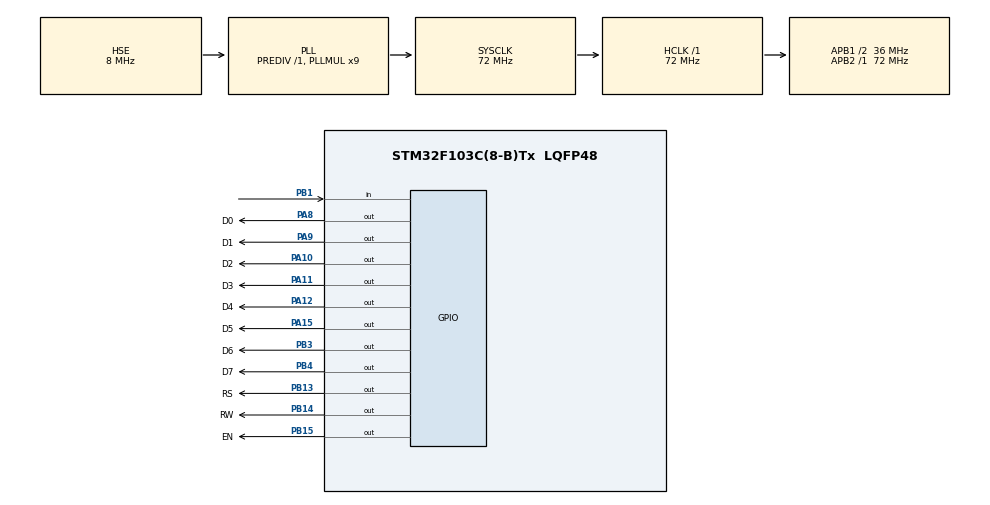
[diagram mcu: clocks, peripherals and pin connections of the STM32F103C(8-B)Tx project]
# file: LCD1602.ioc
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Mcu.Family=STM32F1
Mcu.Name=STM32F103C(8-B)Tx
Mcu.Package=LQFP48
NVIC.PriorityGroup=NVIC_PRIORITYGROUP_4
NVIC.TIM1_UP_IRQn=true\:0\:0\:false\:false\:true\:true\:true\:true
PA10.GPIO_Label=D2
PA10.GPIO_Speed=GPIO_SPEED_FREQ_HIGH
PA10.Signal=GPIO_Output
PA11.GPIO_Label=D3
PA11.GPIO_Speed=GPIO_SPEED_FREQ_HIGH
PA11.Signal=GPIO_Output
PA12.GPIO_Label=D4
PA12.GPIO_Speed=GPIO_SPEED_FREQ_HIGH
PA12.Signal=GPIO_Output
PA13.Mode=Serial_Wire
PA13.Signal=SYS_JTMS-SWDIO
PA14.Mode=Serial_Wire
PA14.Signal=SYS_JTCK-SWCLK
PA15.GPIO_Label=D5
PA15.GPIO_Speed=GPIO_SPEED_FREQ_HIGH
PA15.Signal=GPIO_Output
PA8.GPIO_Label=D0
PA8.GPIO_Speed=GPIO_SPEED_FREQ_HIGH
PA8.Signal=GPIO_Output
PA9.GPIO_Label=D1
PA9.GPIO_Speed=GPIO_SPEED_FREQ_HIGH
PA9.Signal=GPIO_Output
PB1.GPIO_PuPd=GPIO_PULLUP
PB1.Signal=GPIO_Input
PB13.GPIO_Label=RS
PB13.GPIO_Speed=GPIO_SPEED_FREQ_HIGH
PB13.Signal=GPIO_Output
PB14.GPIO_Label=RW
PB14.GPIO_Speed=GPIO_SPEED_FREQ_HIGH
PB14.Signal=GPIO_Output
PB15.GPIO_Label=EN
PB15.GPIO_Speed=GPIO_SPEED_FREQ_HIGH
PB15.Signal=GPIO_Output
PB3.GPIO_Label=D6
PB3.GPIO_Speed=GPIO_SPEED_FREQ_HIGH
PB3.Signal=GPIO_Output
PB4.GPIO_Label=D7
PB4.GPIO_Speed=GPIO_SPEED_FREQ_HIGH
PB4.Signal=GPIO_Output
PD0-OSC_IN.Mode=HSE-External-Oscillator
PD0-OSC_IN.Signal=RCC_OSC_IN
PD1-OSC_OUT.Mode=HSE-External-Oscillator
PD1-OSC_OUT.Signal=RCC_OSC_OUT
ProjectManager.HeapSize=0x00
ProjectManager.StackSize=0x400
ProjectManager.TargetToolchain=MDK-ARM V5.32
RCC.AHBFreq_Value=72000000
RCC.APB1CLKDivider=RCC_HCLK_DIV2
RCC.APB1Freq_Value=36000000
RCC.APB1TimFreq_Value=72000000
RCC.APB2Freq_Value=72000000
RCC.APB2TimFreq_Value=72000000
RCC.HCLKFreq_Value=72000000
RCC.PLLMUL=RCC_PLL_MUL9
RCC.PLLSourceVirtual=RCC_PLLSOURCE_HSE
RCC.SYSCLKFreq_VALUE=72000000
RCC.SYSCLKSource=RCC_SYSCLKSOURCE_PLLCLK
RCC.USBFreq_Value=72000000
TIM1.Period=200-1
TIM1.Prescaler=7200-1
VP_TIM1_VS_ClockSourceINT.Mode=Internal
board=custom

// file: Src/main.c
/* USER CODE BEGIN Header */
/**
 ******************************************************************************
 * @file           : main.c
 * @brief          : Main program body
 ******************************************************************************
 * @attention
 *
 * Copyright (c) 2024 STMicroelectronics.
 * All rights reserved.
 *
 * This software is licensed under terms that can be found in the LICENSE file
 * in the root directory of this software component.
 * If no LICENSE file comes with this software, it is provided AS-IS.
 *
 ******************************************************************************
 */
/* USER CODE END Header */
#include "main.h"
#include "tim.h"
#include "gpio.h"

/* USER CODE BEGIN Includes */
#include "show.h"
/* USER CODE END Includes */

void SystemClock_Config(void);

/* USER CODE BEGIN 0 */
extern uint8_t state;
/* USER CODE END 0 */

int main(void)
{

  /* MCU Configuration--------------------------------------------------------*/

  /* Reset of all peripherals, Initializes the Flash interface and the Systick. */
  HAL_Init();

  /* Configure the system clock */
  SystemClock_Config();

  /* Initialize all configured peripherals */
  MX_GPIO_Init();
  MX_TIM1_Init();
  /* USER CODE BEGIN 2 */
  HAL_TIM_Base_Start_IT(&htim1);

  WriteCommand(0x01); // 清除显示
  WriteCommand(0x06); // AC自增，显示不发生位移
  // WriteCommand(0x0f); // 开显示，游标显示，闪烁
  WriteCommand(0x0c); // 开显示，不游标显示，不闪烁
  WriteCommand(0x3c); // 8位数据总线两行显示

  // 显示
  WriteCommand(0x80); // 设置DDRAM地址
  WriteData('a');
  /* USER CODE END 2 */

  /* Infinite loop */
  /* USER CODE BEGIN WHILE */
  while (1)
  {
    WriteCommand(0x80); // 设置DDRAM地址
    WriteData(state + '0');
    /* USER CODE END WHILE */

  }
}

void SystemClock_Config(void)
{
  RCC_OscInitTypeDef RCC_OscInitStruct = {0};
  RCC_ClkInitTypeDef RCC_ClkInitStruct = {0};

  /** Initializes the RCC Oscillators according to the specified parameters
   * in the RCC_OscInitTypeDef structure.
   */
  RCC_OscInitStruct.OscillatorType = RCC_OSCILLATORTYPE_HSE;
  RCC_OscInitStruct.HSEState = RCC_HSE_ON;
  RCC_OscInitStruct.HSEPredivValue = RCC_HSE_PREDIV_DIV1;
  RCC_OscInitStruct.HSIState = RCC_HSI_ON;
  RCC_OscInitStruct.PLL.PLLState = RCC_PLL_ON;
  RCC_OscInitStruct.PLL.PLLSource = RCC_PLLSOURCE_HSE;
  RCC_OscInitStruct.PLL.PLLMUL = RCC_PLL_MUL9;
  if (HAL_RCC_OscConfig(&RCC_OscInitStruct) != HAL_OK)
  {
    Error_Handler();
  }

  /** Initializes the CPU, AHB and APB buses clocks
   */
  RCC_ClkInitStruct.ClockType = RCC_CLOCKTYPE_HCLK | RCC_CLOCKTYPE_SYSCLK | RCC_CLOCKTYPE_PCLK1 | RCC_CLOCKTYPE_PCLK2;
  RCC_ClkInitStruct.SYSCLKSource = RCC_SYSCLKSOURCE_PLLCLK;
  RCC_ClkInitStruct.AHBCLKDivider = RCC_SYSCLK_DIV1;
  RCC_ClkInitStruct.APB1CLKDivider = RCC_HCLK_DIV2;
  RCC_ClkInitStruct.APB2CLKDivider = RCC_HCLK_DIV1;

  if (HAL_RCC_ClockConfig(&RCC_ClkInitStruct, FLASH_LATENCY_2) != HAL_OK)
  {
    Error_Handler();
  }
}

void Error_Handler(void)
{
  __disable_irq();
  while (1)
  {
  }
}
